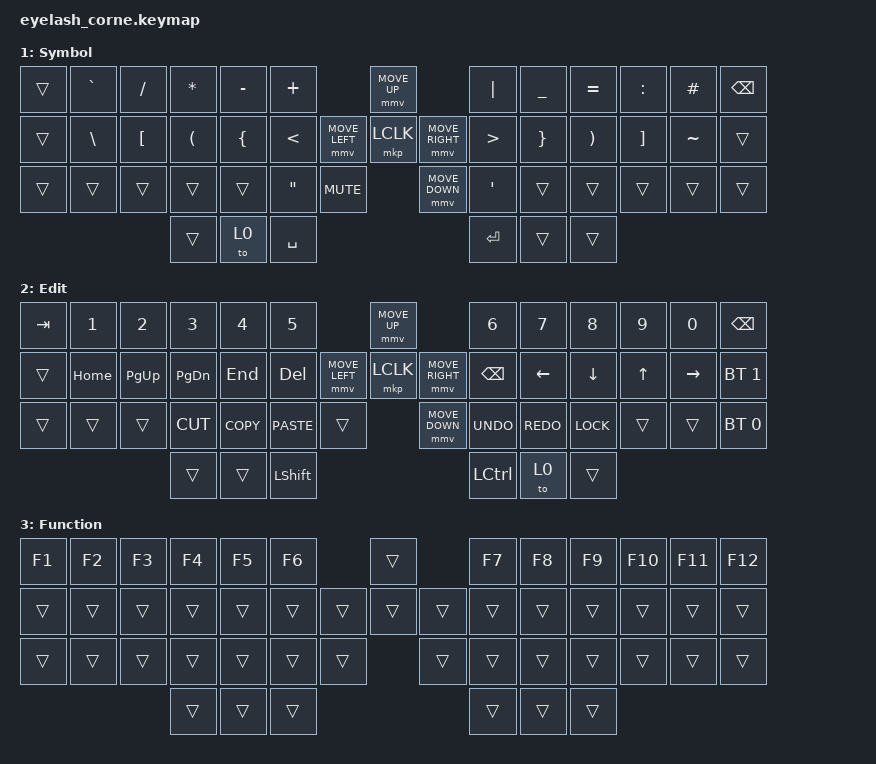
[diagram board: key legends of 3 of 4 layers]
#include <zephyr/dt-bindings/input/input-event-codes.h>
#include <behaviors.dtsi>
#include <dt-bindings/zmk/bt.h>
#include <dt-bindings/zmk/keys.h>
#include <dt-bindings/zmk/pointing.h>
#include <dt-bindings/zmk/rgb.h>

&soft_off { hold-time-ms = <2000>; };

/ {
    behaviors {
        td0: td0 {
            compatible = "zmk,behavior-tap-dance";
            display-name = "Shift/Caps Lock Tap Dance";
            #binding-cells = <0>;
            bindings = <&kp LEFT_SHIFT>, <&kp CAPS>;
        };

        td_mo2: td_mo2 {
            compatible = "zmk,behavior-tap-dance";
            #binding-cells = <0>;
            tapping-term-ms = <250>;
            bindings = <&mo 2>, <&to 2>;
        };

        td_mo1: td_mo1 {
            compatible = "zmk,behavior-tap-dance";
            #binding-cells = <0>;
            tapping-term-ms = <250>;
            bindings = <&mo 1>, <&to 1>;
        };

        space_shift: space_shift {
            compatible = "zmk,behavior-hold-tap";
            #binding-cells = <2>;
            flavor = "hold-preferred";
            tapping-term-ms = <160>;
            require-prior-idle-ms = <120>;
            bindings = <&kp>, <&kp>;
        };
    };

    rgb_encoder: rgb_encoder {
        compatible = "zmk,behavior-sensor-rotate";
        #sensor-binding-cells = <0>;
        bindings = <&rgb_ug RGB_BRI>, <&rgb_ug RGB_BRD>;
    };

    combos {
        compatible = "zmk,combos";

        softoff {
            bindings = <&soft_off>;
            key-positions = <1 15 29>;
        };

        layer3_combo {
            bindings = <&mo 3>;
            key-positions = <42 47>;
        };
    };

    keymap {
        compatible = "zmk,keymap";

        default_layer {
            display-name = "QWERTY";
            bindings = <
&kp TAB       &kp Q  &kp W  &kp E    &kp R           &kp T                             &kp UP                &kp Y        &kp U          &kp I      &kp O    &kp P     &kp SQT
&kp LEFT_WIN  &kp A  &kp S  &kp D    &kp F           &kp G                   &kp LEFT  &kp ENTER  &kp RIGHT  &kp H        &kp J          &kp K      &kp L    &kp SEMI  &kp RALT
&kp LCTRL     &kp Z  &kp X  &kp C    &kp V           &kp B      &kp SPACE              &kp DOWN              &kp N        &kp M          &kp COMMA  &kp DOT  &kp FSLH  &kp ESC
                            &kp TAB  &td_mo1         &space_shift LEFT_SHIFT SPACE                          &lt 0 ENTER  &lt 2 BACKSPACE  &td_mo2  &kp DEL 
            >;

            sensor-bindings = <&inc_dec_kp C_VOLUME_UP C_VOL_DN>;
        };

        lower_layer {
            display-name = "Symbol";
            bindings = <
&trans  &kp GRAVE      &kp SLASH         &kp ASTRK             &kp MINUS       &kp PLUS                                         &mmv MOVE_UP                     &kp PIPE          &kp UNDER        &kp EQUAL              &kp COLON          &kp HASH   &kp BSPC
&trans  &kp BACKSLASH  &kp LEFT_BRACKET  &kp LEFT_PARENTHESIS  &kp LEFT_BRACE  &kp LT                           &mmv MOVE_LEFT  &mkp LCLK       &mmv MOVE_RIGHT  &kp GT            &kp RIGHT_BRACE  &kp RIGHT_PARENTHESIS  &kp RIGHT_BRACKET  &kp TILDE  &trans
&trans  &trans         &trans            &trans                &trans          &kp DOUBLE_QUOTES  &kp C_MUTE                    &mmv MOVE_DOWN                   &kp SINGLE_QUOTE  &trans           &trans                 &trans             &trans     &trans
                                         &trans                &to 0           &kp SPACE                                                                         &kp ENTER         &trans           &trans
            >;

            sensor-bindings = <&inc_dec_kp C_VOLUME_UP C_VOL_DN>;
        };

        raise_layer {
            display-name = "Edit";
            bindings = <
&kp TAB  &kp NUMBER_1  &kp N2       &kp NUMBER_3   &kp NUMBER_4  &kp N5                                    &mmv MOVE_UP                     &kp NUMBER_6   &kp N7          &kp N8      &kp N9        &kp N0     &kp BSPC
&trans   &kp HOME      &kp PAGE_UP  &kp PAGE_DOWN  &kp END       &kp DEL                   &mmv MOVE_LEFT  &mkp LCLK       &mmv MOVE_RIGHT  &kp BACKSPACE  &kp LEFT_ARROW  &kp DOWN    &kp UP_ARROW  &kp RIGHT  &bt BT_SEL 1
&trans   &trans        &trans       &kp K_CUT      &kp K_COPY    &kp K_PASTE     &trans                    &mmv MOVE_DOWN                   &kp K_UNDO     &kp K_REDO      &kp K_LOCK  &trans        &trans     &bt BT_SEL 0
                                    &trans         &trans        &kp LEFT_SHIFT                                                             &kp LCTRL      &to 0           &trans
            >;

            sensor-bindings = <&inc_dec_kp C_VOLUME_UP C_VOL_DN>;
        };

        layer_3 {
            bindings = <
&kp F1  &kp F2  &kp F3  &kp F4  &kp F5  &kp F6                    &trans          &kp F7  &kp F8  &kp F9  &kp F10  &kp F11  &kp F12
&trans  &trans  &trans  &trans  &trans  &trans            &trans  &trans  &trans  &trans  &trans  &trans  &trans   &trans   &trans
&trans  &trans  &trans  &trans  &trans  &trans  &trans            &trans          &trans  &trans  &trans  &trans   &trans   &trans
                        &trans  &trans  &trans                                    &trans  &trans  &trans
            >;

            label = "Function";
        };
    };
};
